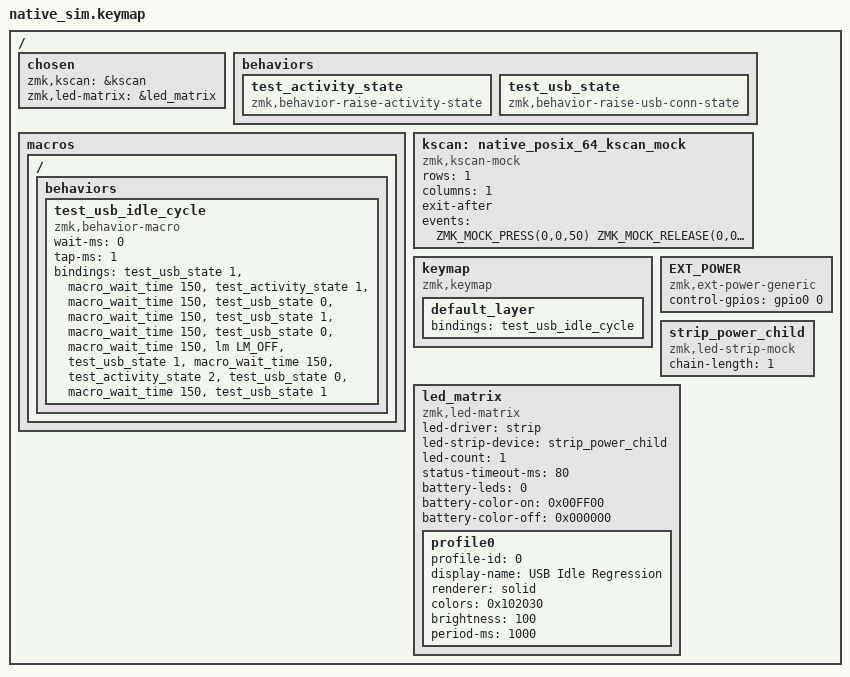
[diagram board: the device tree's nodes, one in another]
#include <dt-bindings/zmk/kscan_mock.h>
#include <dt-bindings/zmk/led_matrix.h>
#include <behaviors.dtsi>

/ {
    chosen {
        zmk,kscan = &kscan;
        zmk,led-matrix = &led_matrix;
    };
    behaviors {
        test_activity_state: test_activity_state {
            compatible = "zmk,behavior-raise-activity-state";
            #binding-cells = <1>;
        };
        test_usb_state: test_usb_state {
            compatible = "zmk,behavior-raise-usb-conn-state";
            #binding-cells = <1>;
        };
    };
    macros {
        ZMK_MACRO(test_usb_idle_cycle,
            wait-ms = <0>;
            tap-ms = <1>;
            bindings
                = <&test_usb_state 1>
                , <&macro_wait_time 150>
                , <&test_activity_state 1>
                , <&macro_wait_time 150>
                , <&test_usb_state 0>
                , <&macro_wait_time 150>
                , <&test_usb_state 1>
                , <&macro_wait_time 150>
                , <&test_usb_state 0>
                , <&macro_wait_time 150>
                , <&lm LM_OFF>
                , <&test_usb_state 1>
                , <&macro_wait_time 150>
                , <&test_activity_state 2>
                , <&test_usb_state 0>
                , <&macro_wait_time 150>
                , <&test_usb_state 1>
                ;
        )
    };
    kscan: native_posix_64_kscan_mock {
        compatible = "zmk,kscan-mock";
        rows = <1>;
        columns = <1>;
        exit-after;
        events = <ZMK_MOCK_PRESS(0,0,50) ZMK_MOCK_RELEASE(0,0,3000)>;
    };
    keymap {
        compatible = "zmk,keymap";
        default_layer { bindings = <&test_usb_idle_cycle>; };
    };
    EXT_POWER {
        compatible = "zmk,ext-power-generic";
        control-gpios = <&gpio0 0 GPIO_ACTIVE_HIGH>;
    };
    strip_power_child: strip_power_child {
        compatible = "zmk,led-strip-mock";
        chain-length = <1>;
    };
    led_matrix: led_matrix {
        compatible = "zmk,led-matrix";
        led-driver = "strip";
        led-strip-device = <&strip_power_child>;
        led-count = <1>;
        status-timeout-ms = <80>;
        battery-leds = <0>;
        battery-color-on = <0x00FF00>;
        battery-color-off = <0x000000>;
        profile0 {
            profile-id = <0>;
            display-name = "USB Idle Regression";
            renderer = "solid";
            colors = <0x102030>;
            brightness = <100>;
            period-ms = <1000>;
        };
    };
};
